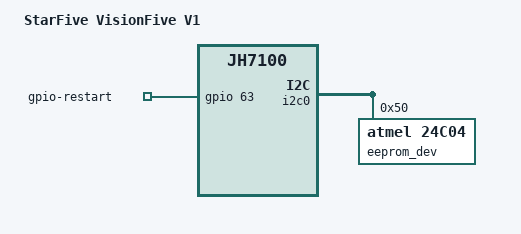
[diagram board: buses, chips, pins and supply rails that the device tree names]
// SPDX-License-Identifier: (GPL-2.0 OR MIT)
/* Copyright (c) 2021 Jianlong Huang <jianlong.huang@starfivetech.com> */

/dts-v1/;
#include "jh7100-beaglev-starlight.dts"

/ {
	model = "StarFive VisionFive V1";

	gpio-restart {
		compatible = "gpio-restart";
		gpios = <&gpio 63 GPIO_ACTIVE_HIGH>;
		priority = <256>;
	};
};

&gmac {
	/delete-property/ snps,reset-gpios;
};

&gpio {
	/* don't reset gpio mux for serial console and reset gpio */
	starfive,keep-gpiomux = <13 14 63 0 2 3 45>;
};

&i2c0 {
	eeprom_dev:eeprom@50 {
		compatible = "atmel,24c04";
		reg = <0x50>;
		pagesize = <16>;
	};
};

